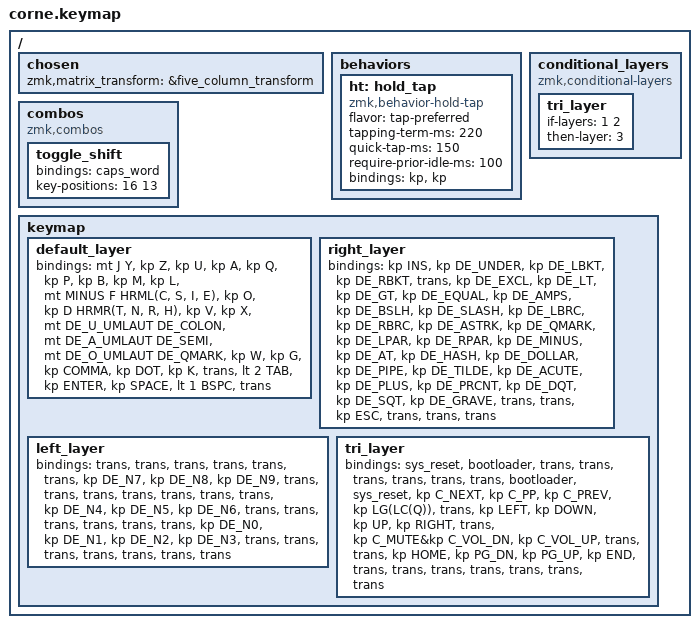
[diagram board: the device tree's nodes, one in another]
/*
 * Copyright (c) 2020 The ZMK Contributors
 *
 * SPDX-License-Identifier: MIT
 */

#include <behaviors.dtsi>
#include <dt-bindings/zmk/bt.h>
#include <dt-bindings/zmk/keys.h>
#include <dt-bindings/zmk/keys.h>

#define DEFAULT_L 0

// Home row mods macro
#define HRML(k1,k2,k3,k4) &ht LSHFT k1  &ht LALT k2  &ht LCTRL k3  &ht LGUI k4
#define HRMR(k1,k2,k3,k4) &ht RGUI k1  &ht RCTRL k2  &ht RALT k3  &ht RSHFT k4




/ {
    chosen { zmk,matrix_transform = &five_column_transform; };
        behaviors {
             ht: hold_tap {
                compatible = "zmk,behavior-hold-tap";
                #binding-cells = <2>;
                flavor = "tap-preferred";
                tapping-term-ms = <220>;
                quick-tap-ms = <150>;
                require-prior-idle-ms = <100>;
                bindings = <&kp>, <&kp>;
        };
    };

    conditional_layers {
        compatible = "zmk,conditional-layers";
        tri_layer {
            if-layers = <1 2>;
            then-layer = <3>;
        };
    };

    combos {
        compatible = "zmk,combos";

        toggle_shift {
            bindings = <&caps_word>;
            key-positions = <16 13>;
        };
    };

    keymap {
        default_layer {
            bindings = <
        //╭──────────┬──────────┬──────────┬──────────┬──────────╮   ╭──────────┬──────────┬──────────┬──────────┬──────────╮
        //│  Z       │  Y       │  U       │  A       │  Q       │   │  P       │  B       │  M       │  L       │  F       │
            &mt J Y      &kp Z      &kp U      &kp A      &kp Q          &kp P      &kp B      &kp M      &kp L   &mt MINUS F
        //├──────────┼──────────┼──────────┼──────────┼──────────┤   ├──────────┼──────────┼──────────┼──────────┼──────────┤
        //│  C       │  S       │  I       │  E       │  O       │   │  D       │  T       │  N       │  R       │   H      │
            HRML(C,        S,         I,         E)     &kp O          &kp D      HRMR(T,        N,         R,        H)
        //├──────────┼──────────┼──────────┼──────────┼──────────┤   ├──────────┼──────────┼──────────┼──────────┼──────────┤
        //│  V       │  X       │  Ü       │  Ä       │  Ö       │   │  N       │  M       │ , <      │ . >      │ K        │
            &kp V      &kp X     &mt DE_U_UMLAUT DE_COLON &mt DE_A_UMLAUT DE_SEMI &mt DE_O_UMLAUT DE_QMARK &kp W  &kp G &kp COMMA &kp DOT &kp K
        //╰──────────┴──────────┴──────────┼──────────┼──────────┤   ├──────────┼──────────┼──────────┴──────────┴──────────╯
                                   &trans     &lt 2 TAB   &kp ENTER     &kp SPACE  &lt 1 BSPC &trans
        //                      ╰──────────┴──────────┴──────────╯   ╰──────────┴──────────┴──────────╯
            >;
        };
 
        right_layer {
            bindings = <
        // zeichen
        //╭──────────┬──────────┬──────────┬──────────┬──────────╮   ╭──────────┬──────────┬──────────┬──────────┬──────────╮
        //│ trans    │  _       │  [       │  ]       │ ^        │   │ !        │ <        │ >        │ =        │  &       │
            &kp INS    &kp DE_UNDER &kp DE_LBKT &kp DE_RBKT &trans  &kp DE_EXCL &kp DE_LT  &kp DE_GT  &kp DE_EQUAL &kp DE_AMPS  
        //├──────────┼──────────┼──────────┼──────────┼──────────┤   ├──────────┼──────────┼──────────┼──────────┼──────────┤
        //│ \        │  /       │  {       │  }       │   *      │   │ ?        │ (        │ )        │ -        │  @       │
           &kp DE_BSLH &kp DE_SLASH &kp DE_LBRC &kp DE_RBRC &kp DE_ASTRK   &kp DE_QMARK &kp DE_LPAR &kp DE_RPAR &kp DE_MINUS &kp DE_AT
        //├──────────┼──────────┼──────────┼──────────┼──────────┤   ├──────────┼──────────┼──────────┼──────────┼──────────┤
        //│ #        │  $       │  |       │  ~       │  `       │   │  +       │   %      │  "       │  '       │          │
         &kp DE_HASH  &kp DE_DOLLAR  &kp DE_PIPE  &kp DE_TILDE &kp DE_ACUTE &kp DE_PLUS &kp DE_PRCNT &kp DE_DQT &kp DE_SQT &kp DE_GRAVE
        //╰──────────┴──────────┴──────────┼──────────┼──────────┤   ├──────────┼──────────┼──────────┴──────────┴──────────╯
                                  &trans     &trans     &kp ESC         &trans     &trans     &trans
        //                      ╰──────────┴──────────┴──────────╯   ╰──────────┴──────────┴──────────╯
            >;
        };

        left_layer {
            bindings = <
        //╭──────────┬──────────┬──────────┬──────────┬──────────╮   ╭──────────┬──────────┬──────────┬──────────┬──────────╮
        //│          │          │          │          │          │   │          │  7       │  8       │  9       │          │
             &trans     &trans     &trans     &trans     &trans        &trans    &kp DE_N7  &kp DE_N8 &kp DE_N9   &trans
        //├──────────┼──────────┼──────────┼──────────┼──────────┤   ├──────────┼──────────┼──────────┼──────────┼──────────┤
        //│          │          │          │          │          │   │          │  4       │  5       │  6       │          │
             &trans     &trans     &trans     &trans     &trans       &trans     &kp DE_N4  &kp DE_N5  &kp DE_N6   &trans
        //├──────────┼──────────┼──────────┼──────────┼──────────┤   ├──────────┼──────────┼──────────┼──────────┼──────────┤
        //│          │          │          │          │          │   │  0       │  1       │  2       │  3       │          │
            &trans     &trans     &trans     &trans     &trans         &kp DE_N0 &kp DE_N1  &kp DE_N2   &kp DE_N3   &trans
        //╰──────────┴──────────┴──────────┼──────────┼──────────┤   ├──────────┼──────────┼──────────┴──────────┴──────────╯
                                  &trans     &trans     &trans         &trans     &trans     &trans
        //                      ╰──────────┴──────────┴──────────╯   ╰──────────┴──────────┴──────────╯
            >;
        };

        tri_layer {
            bindings = <
        //╭──────────┬──────────┬──────────┬──────────┬──────────╮   ╭──────────┬──────────┬──────────┬──────────┬──────────╮
        //│ RESET    │          │          │          │          │   │          │          │          │          │  RESET   │
           &sys_reset  &bootloader &trans     &trans    &trans        &trans     &trans     &trans   &bootloader    &sys_reset
        //├──────────┼──────────┼──────────┼──────────┼──────────┤   ├──────────┼──────────┼──────────┼──────────┼──────────┤
        //│          │          │          │          │          │   │          │          │          │          │          │
          &kp C_NEXT  &kp C_PP &kp C_PREV     &kp LG(LC(Q))    &trans        &kp LEFT   &kp DOWN   &kp UP     &kp RIGHT    &trans
        //├──────────┼──────────┼──────────┼──────────┼──────────┤   ├──────────┼──────────┼──────────┼──────────┼──────────┤
        //│          │          │          │          │          │   │          │          │          │          │          │
           &kp C_MUTE&kp C_VOL_DN &kp C_VOL_UP    &trans      &trans  &kp HOME     &kp PG_DN   &kp PG_UP &kp END     &trans
        //╰──────────┴──────────┴──────────┼──────────┼──────────┤   ├──────────┼──────────┼──────────┴──────────┴──────────╯
                                  &trans     &trans     &trans         &trans     &trans     &trans
        //                      ╰──────────┴──────────┴──────────╯   ╰──────────┴──────────┴──────────╯
            >;
        };
    };
};
